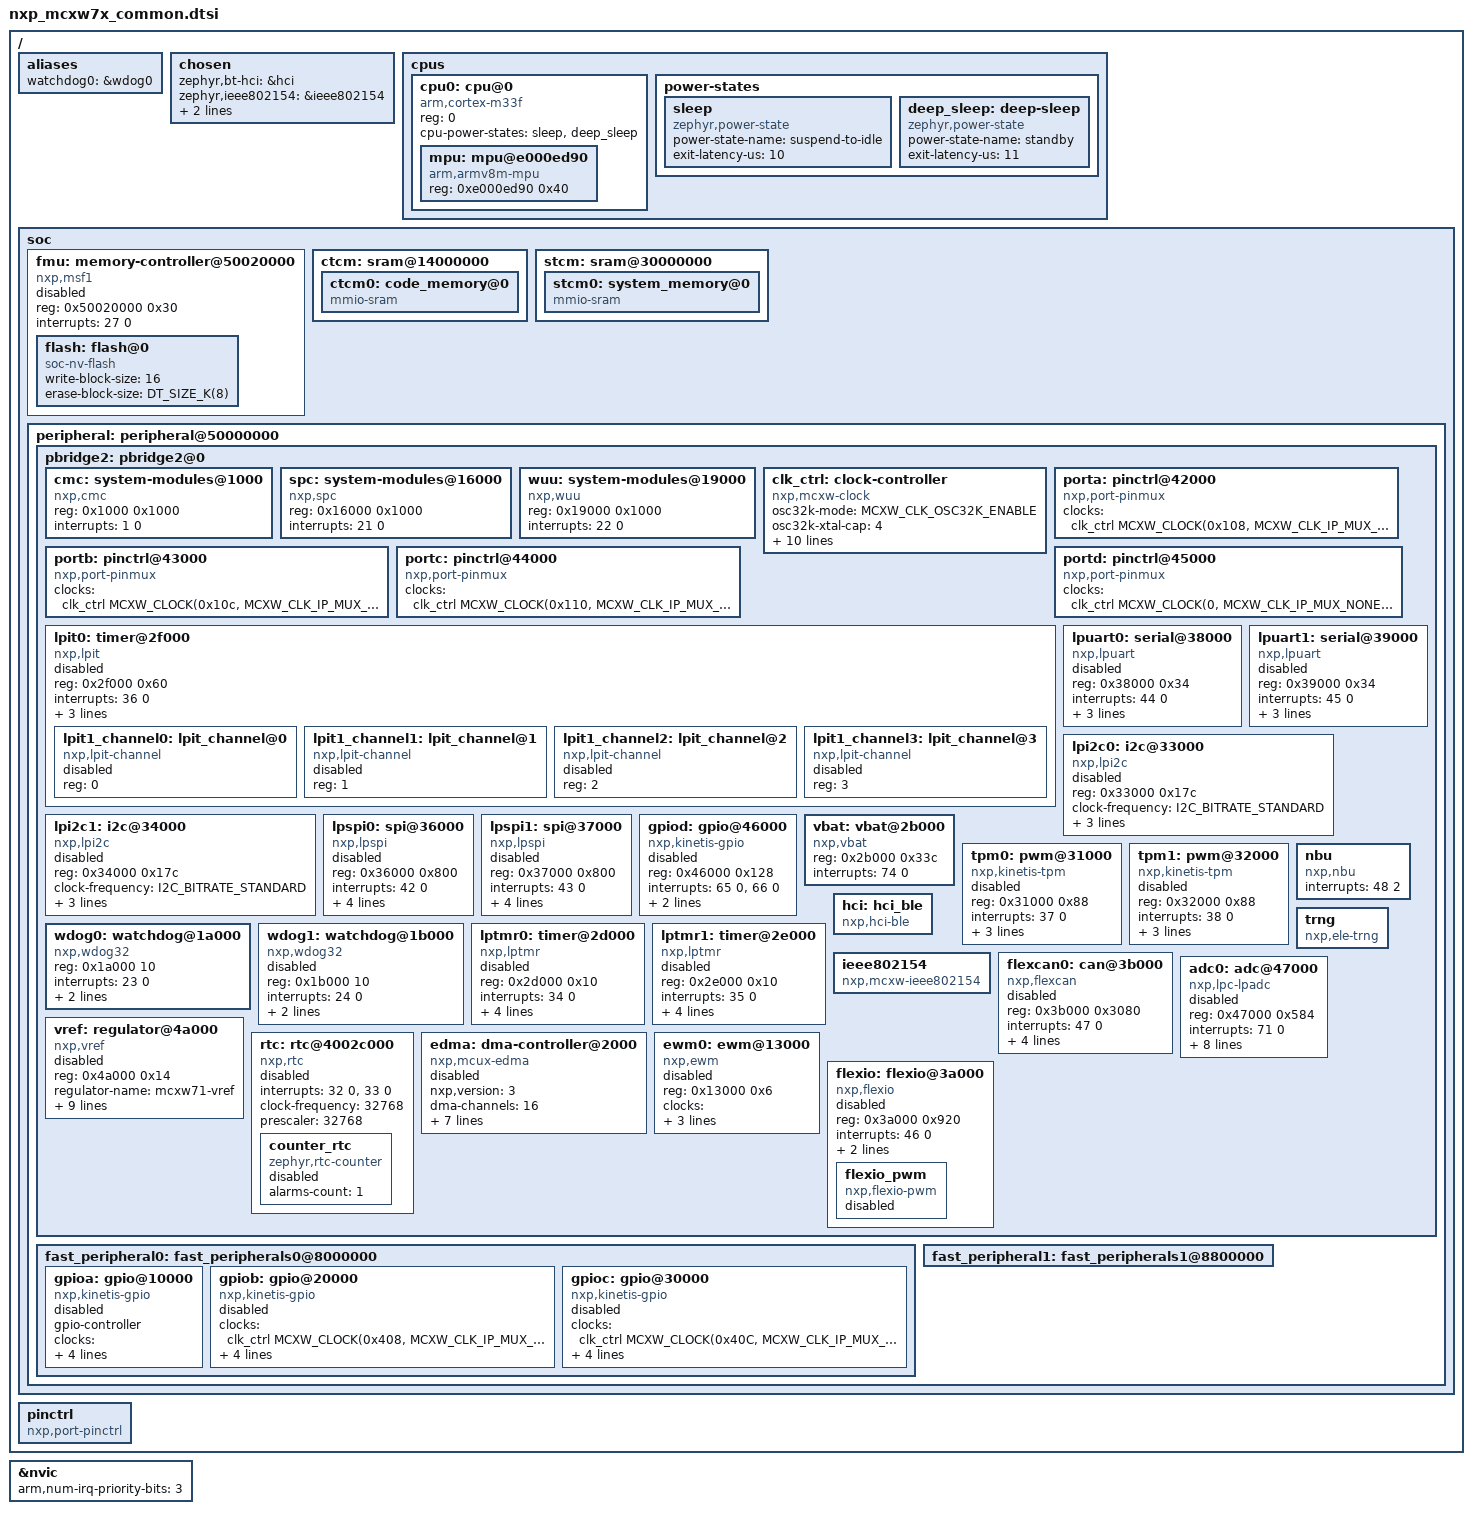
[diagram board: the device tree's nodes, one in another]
/*
 * Copyright 2024-2026 NXP
 *
 * SPDX-License-Identifier: Apache-2.0
 */

#include <mem.h>
#include <freq.h>
#include <arm/armv8-m.dtsi>
#include <zephyr/dt-bindings/clock/nxp_mcxw_clock.h>
#include <zephyr/dt-bindings/gpio/gpio.h>
#include <zephyr/dt-bindings/pwm/pwm.h>
#include <zephyr/dt-bindings/i2c/i2c.h>
#include <zephyr/dt-bindings/memory-attr/memory-attr-arm.h>

/ {
	aliases {
		watchdog0 = &wdog0;
	};

	chosen {
		zephyr,bt-hci = &hci;
		zephyr,ieee802154 = &ieee802154;
		zephyr,entropy = &trng;
		zephyr,nbu = &nbu;
	};

	cpus {
		#address-cells = <1>;
		#size-cells = <0>;

		cpu0: cpu@0 {
			compatible = "arm,cortex-m33f";
			reg = <0>;
			cpu-power-states = <&sleep &deep_sleep>;
			#address-cells = <1>;
			#size-cells = <1>;

			mpu: mpu@e000ed90 {
				compatible = "arm,armv8m-mpu";
				reg = <0xe000ed90 0x40>;
			};
		};

		power-states {
			sleep: sleep {
				compatible = "zephyr,power-state";
				power-state-name = "suspend-to-idle";
				exit-latency-us = <10>;
			};

			deep_sleep: deep-sleep {
				compatible = "zephyr,power-state";
				power-state-name = "standby";
				exit-latency-us = <11>;
			};
		};
	};

	soc {
		fmu: memory-controller@50020000 {
			#address-cells = <1>;
			#size-cells = <1>;
			compatible = "nxp,msf1";
			reg = <0x50020000 0x30>;
			interrupts = <27 0>;
			status = "disabled";

			flash: flash@0 {
				compatible = "soc-nv-flash";
				write-block-size = <16>;
				erase-block-size = <DT_SIZE_K(8)>;
			};
		};

		ctcm: sram@14000000 {
			#address-cells = <1>;
			#size-cells = <1>;

			ctcm0: code_memory@0 {
				compatible = "mmio-sram";
			};
		};

		stcm: sram@30000000 {
			#address-cells = <1>;
			#size-cells = <1>;

			stcm0: system_memory@0 {
				compatible = "mmio-sram";
			};
		};

		peripheral: peripheral@50000000 {
			ranges = <0x0 0x50000000 0x10000000>;
			#address-cells = <1>;
			#size-cells = <1>;

			pbridge2: pbridge2@0 {
				ranges;
				#address-cells = <1>;
				#size-cells = <1>;
			};

			fast_peripheral0: fast_peripherals0@8000000 {
				#address-cells = <1>;
				#size-cells = <1>;
				ranges = <0x0 0x8000000 0x40000>;
			};

			fast_peripheral1: fast_peripherals1@8800000 {
				#address-cells = <1>;
				#size-cells = <1>;
				ranges = <0x0 0x8800000 0x20a000>;
			};
		};
	};

	pinctrl: pinctrl {
		compatible = "nxp,port-pinctrl";
	};
};

&nvic {
	arm,num-irq-priority-bits = <3>;
};

&pbridge2 {
	#address-cells = <1>;
	#size-cells = <1>;

	cmc: system-modules@1000 {
		compatible = "nxp,cmc";
		reg = <0x1000 0x1000>;
		interrupts = <1 0>;
	};

	spc: system-modules@16000 {
		compatible = "nxp,spc";
		reg = <0x16000 0x1000>;
		interrupts = <21 0>;
	};

	wuu: system-modules@19000 {
		compatible = "nxp,wuu";
		reg = <0x19000 0x1000>;
		interrupts = <22 0>;
	};

	clk_ctrl: clock-controller {
		compatible = "nxp,mcxw-clock";
		osc32k-mode = <MCXW_CLK_OSC32K_ENABLE>;
		osc32k-xtal-cap = <4>;
		osc32k-extal-cap = <4>;
		firc-mode = <MCXW_CLK_FIRC_ENABLE>;
		firc-range = <MCXW_CLK_FIRC_RANGE_96MHZ>;
		enable-sirc-in-lp-mode;
		sys-clk-src = <MCXW_CLK_SYSTEM_CLK_SRC_FIRC>;
		sys-clk-div-bus = <1>;
		sys-clk-div-slow = <4>;
		sys-clk-div-core = <1>;
		enable-sosc;
		sosc-freq = <DT_FREQ_M(32)>;
		#clock-cells = <1>;
	};

	porta: pinctrl@42000 {
		compatible = "nxp,port-pinmux";
		clocks = <&clk_ctrl MCXW_CLOCK(0x108, MCXW_CLK_IP_MUX_NONE,
								MCXW_CLK_DIV_NONE,
								MCXW_CLK_MODE_ENABLED_LP_STALL)>;
	};

	portb: pinctrl@43000 {
		compatible = "nxp,port-pinmux";
		clocks = <&clk_ctrl MCXW_CLOCK(0x10c, MCXW_CLK_IP_MUX_NONE,
								MCXW_CLK_DIV_NONE,
								MCXW_CLK_MODE_ENABLED_LP_STALL)>;
	};

	portc: pinctrl@44000 {
		compatible = "nxp,port-pinmux";
		clocks = <&clk_ctrl MCXW_CLOCK(0x110, MCXW_CLK_IP_MUX_NONE,
								MCXW_CLK_DIV_NONE,
								MCXW_CLK_MODE_ENABLED_LP_STALL)>;
	};

	portd: pinctrl@45000 {
		compatible = "nxp,port-pinmux";
		clocks = <&clk_ctrl MCXW_CLOCK(0, MCXW_CLK_IP_MUX_NONE,
								MCXW_CLK_DIV_NONE,
								MCXW_CLK_MODE_ENABLED_LP_STALL)>;
	};

	lpit0: timer@2f000 {
		compatible = "nxp,lpit";
		reg = <0x2f000 0x60>;
		interrupts = <36 0>;
		clocks = <&clk_ctrl MCXW_CLOCK(0xbc, MCXW_CLK_IP_MUX_FRO_192M_DIV,
								MCXW_CLK_DIV_NONE,
								MCXW_CLK_MODE_ENABLED_LP_STALL)>;
		status = "disabled";
		max-load-value = <0xffffffff>;
		#address-cells = <1>;
		#size-cells = <0>;

		lpit1_channel0: lpit_channel@0 {
			compatible = "nxp,lpit-channel";
			reg = <0>;
			status = "disabled";
		};

		lpit1_channel1: lpit_channel@1 {
			compatible = "nxp,lpit-channel";
			reg = <1>;
			status = "disabled";
		};

		lpit1_channel2: lpit_channel@2 {
			compatible = "nxp,lpit-channel";
			reg = <2>;
			status = "disabled";
		};

		lpit1_channel3: lpit_channel@3 {
			compatible = "nxp,lpit-channel";
			reg = <3>;
			status = "disabled";
		};
	};

	lpuart0: serial@38000 {
		compatible = "nxp,lpuart";
		reg = <0x38000 0x34>;
		interrupts = <44 0>;
		clocks = <&clk_ctrl MCXW_CLOCK(0xe0, MCXW_CLK_IP_MUX_FRO_192M_DIV,
								MCXW_CLK_DIV_NONE,
								MCXW_CLK_MODE_ENABLED_LP_STALL)>;
		dmas = <&edma 0 32>, <&edma 1 31>;
		dma-names = "tx", "rx";
		status = "disabled";
	};

	lpuart1: serial@39000 {
		compatible = "nxp,lpuart";
		reg = <0x39000 0x34>;
		interrupts = <45 0>;
		clocks = <&clk_ctrl MCXW_CLOCK(0xe4, MCXW_CLK_IP_MUX_FRO_192M_DIV,
								MCXW_CLK_DIV_NONE,
								MCXW_CLK_MODE_ENABLED_LP_STALL)>;
		dmas = <&edma 2 34>, <&edma 3 33>;
		dma-names = "tx", "rx";
		status = "disabled";
	};

	lpi2c0: i2c@33000 {
		compatible = "nxp,lpi2c";
		reg = <0x33000 0x17c>;
		clock-frequency = <I2C_BITRATE_STANDARD>;
		#address-cells = <1>;
		#size-cells = <0>;
		interrupts = <39 0>;
		clocks = <&clk_ctrl MCXW_CLOCK(0xe0, MCXW_CLK_IP_MUX_FRO_192M_DIV,
								MCXW_CLK_DIV_BY_16,
								MCXW_CLK_MODE_ENABLED_LP_STALL)>;
		status = "disabled";
	};

	lpi2c1: i2c@34000 {
		compatible = "nxp,lpi2c";
		reg = <0x34000 0x17c>;
		clock-frequency = <I2C_BITRATE_STANDARD>;
		#address-cells = <1>;
		#size-cells = <0>;
		interrupts = <40 0>;
		clocks = <&clk_ctrl MCXW_CLOCK(0xe4, MCXW_CLK_IP_MUX_FRO_192M_DIV,
								MCXW_CLK_DIV_BY_16,
								MCXW_CLK_MODE_ENABLED_LP_STALL)>;
		status = "disabled";
	};

	lpspi0: spi@36000 {
		compatible = "nxp,lpspi";
		reg = <0x36000 0x800>;
		interrupts = <42 0>;
		clocks = <&clk_ctrl MCXW_CLOCK(0xd8, MCXW_CLK_IP_MUX_FRO_192M_DIV,
								MCXW_CLK_DIV_NONE,
								MCXW_CLK_MODE_ENABLED_LP_STALL)>;
		tx-fifo-size = <8>;
		rx-fifo-size = <8>;
		#address-cells = <1>;
		#size-cells = <0>;
		status = "disabled";
	};

	lpspi1: spi@37000 {
		compatible = "nxp,lpspi";
		reg = <0x37000 0x800>;
		interrupts = <43 0>;
		clocks = <&clk_ctrl MCXW_CLOCK(0xdc, MCXW_CLK_IP_MUX_FRO_192M_DIV,
								MCXW_CLK_DIV_NONE,
								MCXW_CLK_MODE_ENABLED_LP_STALL)>;
		tx-fifo-size = <8>;
		rx-fifo-size = <8>;
		#address-cells = <1>;
		#size-cells = <0>;
		status = "disabled";
	};

	gpiod: gpio@46000 {
		compatible = "nxp,kinetis-gpio";
		reg = <0x46000 0x128>;
		interrupts = <65 0>, <66 0>;
		gpio-controller;
		#gpio-cells = <2>;
		nxp,kinetis-port = <&portd>;
		status = "disabled";
	};

	vbat: vbat@2b000 {
		compatible = "nxp,vbat";
		reg = <0x2b000 0x33c>;
		interrupts = <74 0>;
	};

	tpm0: pwm@31000 {
		compatible = "nxp,kinetis-tpm";
		reg = <0x31000 0x88>;
		interrupts = <37 0>;
		clocks = <&clk_ctrl MCXW_CLOCK(0xc4, MCXW_CLK_IP_MUX_FRO_192M_DIV,
								MCXW_CLK_DIV_NONE,
								MCXW_CLK_MODE_ENABLED_LP_STALL)>;
		prescaler = <16>;
		status = "disabled";
		#pwm-cells = <3>;
	};

	tpm1: pwm@32000 {
		compatible = "nxp,kinetis-tpm";
		reg = <0x32000 0x88>;
		interrupts = <38 0>;
		clocks = <&clk_ctrl MCXW_CLOCK(0xc8, MCXW_CLK_IP_MUX_FRO_192M_DIV,
								MCXW_CLK_DIV_NONE,
								MCXW_CLK_MODE_ENABLED_LP_STALL)>;
		prescaler = <16>;
		status = "disabled";
		#pwm-cells = <3>;
	};

	wdog0: watchdog@1a000 {
		compatible = "nxp,wdog32";
		reg = <0x1a000 10>;
		interrupts = <23 0>;
		clk-source = <1>;
		clk-divider = <1>;
		status = "okay";
	};

	wdog1: watchdog@1b000 {
		compatible = "nxp,wdog32";
		reg = <0x1b000 10>;
		interrupts = <24 0>;
		clk-source = <1>;
		clk-divider = <1>;
		status = "disabled";
	};

	lptmr0: timer@2d000 {
		compatible = "nxp,lptmr";
		reg = <0x2d000 0x10>;
		interrupts = <34 0>;
		clock-frequency = <32768>;
		clk-source = <2>;
		prescale-glitch-filter-bypass;
		resolution = <32>;
		status = "disabled";
	};

	lptmr1: timer@2e000 {
		compatible = "nxp,lptmr";
		reg = <0x2e000 0x10>;
		interrupts = <35 0>;
		clock-frequency = <32768>;
		clk-source = <2>;
		prescale-glitch-filter-bypass;
		resolution = <32>;
		status = "disabled";
	};

	nbu: nbu {
		compatible = "nxp,nbu";
		interrupts = <48 2>;
		interrupt-names = "nbu_rx_int";
	};

	hci: hci_ble {
		compatible = "nxp,hci-ble";
	};

	ieee802154: ieee802154 {
		compatible = "nxp,mcxw-ieee802154";
	};

	trng: trng {
		compatible = "nxp,ele-trng";
	};

	flexcan0: can@3b000 {
		compatible = "nxp,flexcan";
		reg = <0x3b000 0x3080>;
		interrupts = <47 0>;
		interrupt-names = "common";
		clocks = <&clk_ctrl MCXW_CLOCK(0xec, MCXW_CLK_IP_MUX_FRO_192M_DIV,
								MCXW_CLK_DIV_BY_1,
								MCXW_CLK_MODE_ENABLED_LP_STALL)>;
		clock-names = "clksrc0";
		clk-source = <0>;
		number-of-mb = <32>;
		status = "disabled";
	};

	adc0: adc@47000 {
		compatible = "nxp,lpc-lpadc";
		reg = <0x47000 0x584>;
		interrupts = <71 0>;
		clocks = <&clk_ctrl MCXW_CLOCK(0x11c, MCXW_CLK_IP_MUX_FRO_192M_DIV,
								MCXW_CLK_DIV_BY_10,
								MCXW_CLK_MODE_ENABLED_LP_STALL)>;
		voltage-ref = <1>;
		calibration-average = <128>;
		/* pwrlvl 0 is slow speed low power, 1 is opposite */
		power-level = <0>;
		offset-value-a = <0>;
		offset-value-b = <0>;
		#io-channel-cells = <1>;
		nxp,references = <&vref 1800>;
		status = "disabled";
	};

	vref: regulator@4a000 {
		compatible = "nxp,vref";
		reg = <0x4a000 0x14>;
		regulator-name = "mcxw71-vref";
		clocks = <&clk_ctrl MCXW_CLOCK(0x128, MCXW_CLK_IP_MUX_NONE,
								MCXW_CLK_DIV_NONE,
								MCXW_CLK_MODE_ENABLED_LP_STALL)>;
		#nxp,reference-cells = <1>;
		nxp,buffer-startup-delay-us = <400>;
		nxp,bandgap-startup-time-us = <20>;
		regulator-min-microvolt = <1000000>;
		regulator-max-microvolt = <2100000>;
		nxp,current-compensation-en;
		nxp,internal-voltage-regulator-en;
		nxp,chop-oscillator-en;
		status = "disabled";
	};

	rtc: rtc@4002c000 {
		compatible = "nxp,rtc";
		status = "disabled";
		interrupts = <32 0>, <33 0>;
		interrupt-names = "alarm", "seconds";
		clock-frequency = <32768>;
		prescaler = <32768>;

		counter_rtc: counter_rtc {
			compatible = "zephyr,rtc-counter";
			alarms-count = <1>;
			status = "disabled";
		};
	};

	edma: dma-controller@2000 {
		compatible = "nxp,mcux-edma";
		#dma-cells = <2>;
		nxp,version = <3>;
		dma-channels = <16>;
		dma-requests = <64>;
		reg = <0x2000 0x140>;
		clocks = <&clk_ctrl MCXW_CLOCK(0x410, MCXW_CLK_IP_MUX_NONE,
								MCXW_CLK_DIV_NONE,
								MCXW_CLK_MODE_ENABLED_LP_STALL)>;
		interrupts = <2 0>, <3 0>, <4 0>, <5 0>,
			     <6 0>, <7 0>, <8 0>, <9 0>,
			     <10 0>, <11 0>, <12 0>, <13 0>,
			     <14 0>, <15 0>, <16 0>, <17 0>;
		status = "disabled";
	};

	ewm0: ewm@13000 {
		compatible = "nxp,ewm";
		reg = <0x13000 0x6>;
		clocks = <&clk_ctrl MCXW_CLOCK(0x4c, MCXW_CLK_IP_MUX_NONE,
								MCXW_CLK_DIV_NONE,
								MCXW_CLK_MODE_ENABLED_LP_STALL)>;
		status = "disabled";
		interrupts = <18 0>;
		clk-divider = <0x0>;
	};

	flexio: flexio@3a000 {
		compatible = "nxp,flexio";
		reg = <0x3a000 0x920>;
		interrupts = <46 0>;
		clocks = <&clk_ctrl MCXW_CLOCK(0xe8, MCXW_CLK_IP_MUX_FRO_192M_DIV,
								MCXW_CLK_DIV_BY_6,
								MCXW_CLK_MODE_ENABLED_LP_STALL)>;
		status = "disabled";

		flexio_pwm {
			compatible = "nxp,flexio-pwm";
			#pwm-cells = <3>;
			status = "disabled";
		};
	};
};

&fast_peripheral0 {
	gpioa: gpio@10000 {
		compatible = "nxp,kinetis-gpio";
		status = "disabled";
		gpio-controller;
		clocks = <&clk_ctrl MCXW_CLOCK(0x404, MCXW_CLK_IP_MUX_NONE,
								MCXW_CLK_DIV_NONE,
								MCXW_CLK_MODE_ENABLED_LP_STALL)>;
		#gpio-cells = <2>;
		nxp,kinetis-port = <&porta>;
		reg = <0x10000 0x128>;
		interrupts = <59 0>, <60 0>;
	};

	gpiob: gpio@20000 {
		compatible = "nxp,kinetis-gpio";
		status = "disabled";
		clocks = <&clk_ctrl MCXW_CLOCK(0x408, MCXW_CLK_IP_MUX_NONE,
								MCXW_CLK_DIV_NONE,
								MCXW_CLK_MODE_ENABLED_LP_STALL)>;
		gpio-controller;
		#gpio-cells = <2>;
		nxp,kinetis-port = <&portb>;
		reg = <0x20000 0x128>;
		interrupts = <61 0>, <62 0>;
	};

	gpioc: gpio@30000 {
		compatible = "nxp,kinetis-gpio";
		status = "disabled";
		clocks = <&clk_ctrl MCXW_CLOCK(0x40C, MCXW_CLK_IP_MUX_NONE,
								MCXW_CLK_DIV_NONE,
								MCXW_CLK_MODE_ENABLED_LP_STALL)>;
		gpio-controller;
		#gpio-cells = <2>;
		nxp,kinetis-port = <&portc>;
		reg = <0x30000 0x128>;
		interrupts = <63 0>, <64 0>;
	};
};
